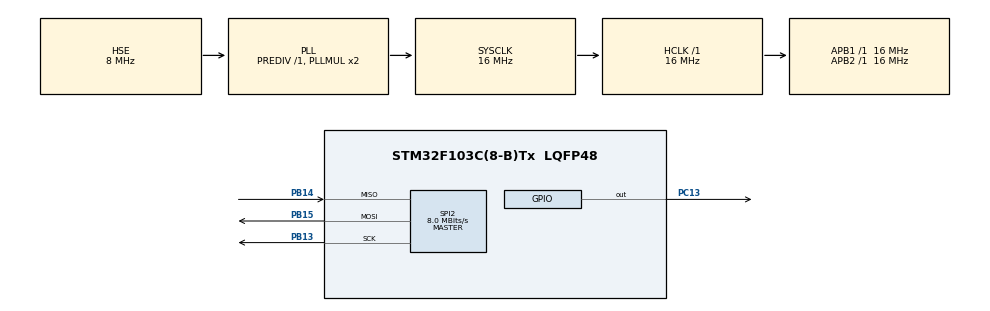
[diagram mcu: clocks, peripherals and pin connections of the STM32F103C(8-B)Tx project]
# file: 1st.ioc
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Mcu.Family=STM32F1
Mcu.Name=STM32F103C(8-B)Tx
Mcu.Package=LQFP48
NVIC.PriorityGroup=NVIC_PRIORITYGROUP_4
PA13.Mode=Serial_Wire
PA13.Signal=SYS_JTMS-SWDIO
PA14.Mode=Serial_Wire
PA14.Signal=SYS_JTCK-SWCLK
PB13.Mode=Full_Duplex_Master
PB13.Signal=SPI2_SCK
PB14.Mode=Full_Duplex_Master
PB14.Signal=SPI2_MISO
PB15.Mode=Full_Duplex_Master
PB15.Signal=SPI2_MOSI
PC13-TAMPER-RTC.Signal=GPIO_Output
PD0-OSC_IN.Mode=HSE-External-Oscillator
PD0-OSC_IN.Signal=RCC_OSC_IN
PD1-OSC_OUT.Mode=HSE-External-Oscillator
PD1-OSC_OUT.Signal=RCC_OSC_OUT
ProjectManager.HeapSize=0x200
ProjectManager.StackSize=0x400
ProjectManager.TargetToolchain=MDK-ARM V5
RCC.AHBFreq_Value=16000000
RCC.APB1Freq_Value=16000000
RCC.APB1TimFreq_Value=16000000
RCC.APB2Freq_Value=16000000
RCC.APB2TimFreq_Value=16000000
RCC.HCLKFreq_Value=16000000
RCC.HSIState=RCC_HSI_ON
RCC.PLLSourceVirtual=RCC_PLLSOURCE_HSE
RCC.SYSCLKFreq_VALUE=16000000
RCC.SYSCLKSource=RCC_SYSCLKSOURCE_PLLCLK
RCC.USBFreq_Value=16000000
SPI2.CalculateBaudRate=8.0 MBits/s
SPI2.Mode=SPI_MODE_MASTER
board=1st

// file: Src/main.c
/**
  ******************************************************************************
  * File Name          : main.c
  * Description        : Main program body
  ******************************************************************************
  *
  * COPYRIGHT(c) 2016 STMicroelectronics
  *
  * Redistribution and use in source and binary forms, with or without modification,
  * are permitted provided that the following conditions are met:
  *   1. Redistributions of source code must retain the above copyright notice,
  *      this list of conditions and the following disclaimer.
  *   2. Redistributions in binary form must reproduce the above copyright notice,
  *      this list of conditions and the following disclaimer in the documentation
  *      and/or other materials provided with the distribution.
  *   3. Neither the name of STMicroelectronics nor the names of its contributors
  *      may be used to endorse or promote products derived from this software
  *      without specific prior written permission.
  *
  * THIS SOFTWARE IS PROVIDED BY THE COPYRIGHT HOLDERS AND CONTRIBUTORS "AS IS"
  * AND ANY EXPRESS OR IMPLIED WARRANTIES, INCLUDING, BUT NOT LIMITED TO, THE
  * IMPLIED WARRANTIES OF MERCHANTABILITY AND FITNESS FOR A PARTICULAR PURPOSE ARE
  * DISCLAIMED. IN NO EVENT SHALL THE COPYRIGHT HOLDER OR CONTRIBUTORS BE LIABLE
  * FOR ANY DIRECT, INDIRECT, INCIDENTAL, SPECIAL, EXEMPLARY, OR CONSEQUENTIAL
  * DAMAGES (INCLUDING, BUT NOT LIMITED TO, PROCUREMENT OF SUBSTITUTE GOODS OR
  * SERVICES; LOSS OF USE, DATA, OR PROFITS; OR BUSINESS INTERRUPTION) HOWEVER
  * CAUSED AND ON ANY THEORY OF LIABILITY, WHETHER IN CONTRACT, STRICT LIABILITY,
  * OR TORT (INCLUDING NEGLIGENCE OR OTHERWISE) ARISING IN ANY WAY OUT OF THE USE
  * OF THIS SOFTWARE, EVEN IF ADVISED OF THE POSSIBILITY OF SUCH DAMAGE.
  *
  ******************************************************************************
  */
#include "stm32f1xx_hal.h"
#include "spi.h"
#include "gpio.h"

/* USER CODE BEGIN Includes */
void BootLoaderInit (uint32_t BootloaderStatus);
/* USER CODE END Includes */

uint8_t SPI_tx_buf[8];
uint8_t SPI_rx_buf[8];
uint8_t f =0x22;
uint8_t ff =0x23;
/* USER CODE BEGIN PV */
/* Private variables ---------------------------------------------------------*/

/* USER CODE END PV */

void SystemClock_Config(void);

/* USER CODE BEGIN PFP */
/* Private function prototypes -----------------------------------------------*/

/* USER CODE END PFP */

int main(void)
{
BootLoaderInit(1);

  /* MCU Configuration----------------------------------------------------------*/

  /* Reset of all peripherals, Initializes the Flash interface and the Systick. */
  HAL_Init();

  /* Configure the system clock */
  SystemClock_Config();

  /* Initialize all configured peripherals */
  MX_GPIO_Init();
  MX_SPI2_Init();

  /* Infinite loop */
  while (1)
  {
		HAL_Delay(1000);
	  HAL_GPIO_WritePin( GPIOB, GPIO_PIN_12, GPIO_PIN_RESET );
		HAL_Delay(10);
	 HAL_SPI_TransmitReceive(&hspi2, &f, &ff, 1, 100);
//		HAL_SPI_Receive(&hspi2, &ff, 1, 10000);//одна 16ти битная передача???
//	HAL_SPI_Transmit(&hspi3, &hh, 1, 100)одна 16ти битная передача???
	HAL_GPIO_WritePin( GPIOB, GPIO_PIN_12, GPIO_PIN_SET );
  }

}
void BootLoaderInit (uint32_t BootloaderStatus)
	{
		void (*SysMemBootJump)(void);
SysMemBootJump = (void (*)(void)) (*((uint32_t *) 0x1FFFF004));

	if(BootloaderStatus==1)
	{

		HAL_RCC_DeInit();
    SysTick->CTRL = 0;
    SysTick->LOAD = 0;
   SysTick->VAL = 0;

	__set_PRIMASK(1);

		__set_MSP(*(uint32_t *)0x20001000);
		//__set_MSP(*(uint32_t *)0x1FFFF000);

		SysMemBootJump();

	while(1);
	}

}

/** System Clock Configuration
*/
void SystemClock_Config(void)
{

  RCC_OscInitTypeDef RCC_OscInitStruct;
  RCC_ClkInitTypeDef RCC_ClkInitStruct;

  RCC_OscInitStruct.OscillatorType = RCC_OSCILLATORTYPE_HSE;
  RCC_OscInitStruct.HSEState = RCC_HSE_ON;
  RCC_OscInitStruct.HSEPredivValue = RCC_HSE_PREDIV_DIV1;
  RCC_OscInitStruct.PLL.PLLState = RCC_PLL_ON;
  RCC_OscInitStruct.PLL.PLLSource = RCC_PLLSOURCE_HSE;
  RCC_OscInitStruct.PLL.PLLMUL = RCC_PLL_MUL2;
  HAL_RCC_OscConfig(&RCC_OscInitStruct);

  RCC_ClkInitStruct.ClockType = RCC_CLOCKTYPE_SYSCLK;
  RCC_ClkInitStruct.SYSCLKSource = RCC_SYSCLKSOURCE_PLLCLK;
  RCC_ClkInitStruct.AHBCLKDivider = RCC_SYSCLK_DIV1;
  RCC_ClkInitStruct.APB1CLKDivider = RCC_HCLK_DIV1;
  RCC_ClkInitStruct.APB2CLKDivider = RCC_HCLK_DIV1;
  HAL_RCC_ClockConfig(&RCC_ClkInitStruct, FLASH_LATENCY_0);

  HAL_SYSTICK_Config(HAL_RCC_GetHCLKFreq()/1000);

  HAL_SYSTICK_CLKSourceConfig(SYSTICK_CLKSOURCE_HCLK);

  /* SysTick_IRQn interrupt configuration */
  HAL_NVIC_SetPriority(SysTick_IRQn, 0, 0);
}

/************************ (C) COPYRIGHT STMicroelectronics *****END OF FILE****/
